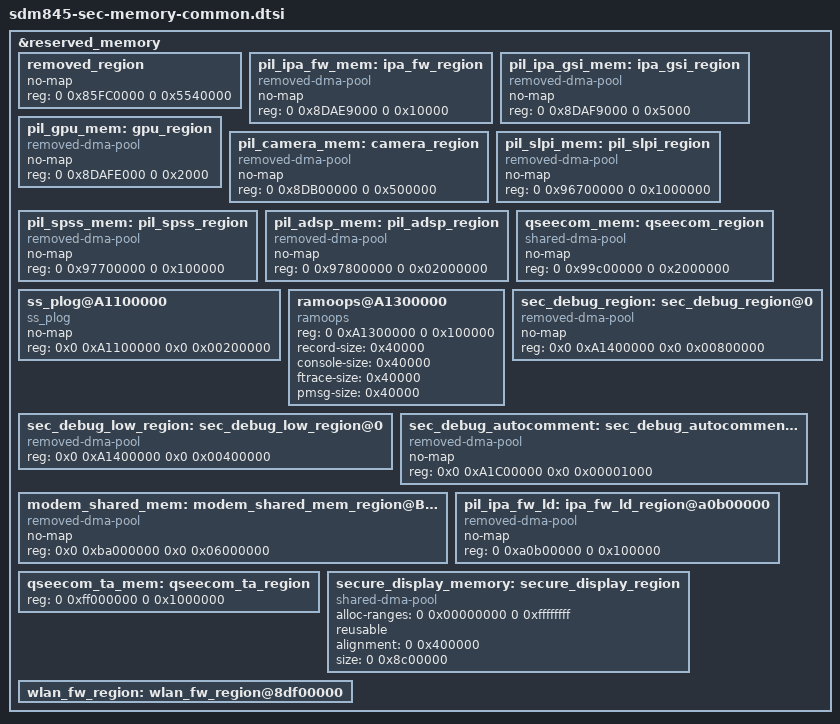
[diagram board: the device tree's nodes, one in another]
/* Copyright (c) 2016-2017, The Linux Foundation. All rights reserved.
 *
 * This program is free software; you can redistribute it and/or modify
 * it under the terms of the GNU General Public License version 2 and
 * only version 2 as published by the Free Software Foundation.
 *
 * This program is distributed in the hope that it will be useful,
 * but WITHOUT ANY WARRANTY; without even the implied warranty of
 * MERCHANTABILITY or FITNESS FOR A PARTICULAR PURPOSE.  See the
 * GNU General Public License for more details.
 */

&reserved_memory {
                /*
                 * Note: For TZapp, need to change XBL(QseeComDxe.h) and
                 *       TZ(oem_config.xml), too.
                 */
                /delete-node/ removed_region@85fc0000;
                removed_region: removed_region {
                        no-map;
                        reg = <0 0x85FC0000 0 0x5540000>;
                };

                /delete-node/ ipa_fw_region@8c400000;
                pil_ipa_fw_mem: ipa_fw_region {
                        compatible = "removed-dma-pool";
                        no-map;
                        reg = <0 0x8DAE9000 0 0x10000>;
                };

                /delete-node/ ipa_gsi_region@8c410000;
                pil_ipa_gsi_mem: ipa_gsi_region{
                        compatible = "removed-dma-pool";
                        no-map;
                        reg = <0 0x8DAF9000 0 0x5000>;
                };

                /delete-node/ gpu_region@8c415000;
                pil_gpu_mem: gpu_region {
                        compatible = "removed-dma-pool";
                        no-map;
                        reg = <0 0x8DAFE000 0 0x2000>;
                };

                /delete-node/ camera_region@8bf00000;
                pil_camera_mem: camera_region {
                        compatible = "removed-dma-pool";
                        no-map;
                        reg = <0 0x8DB00000 0 0x500000>;
                };

                /delete-node/ pil_slpi_region@96700000;
                pil_slpi_mem: pil_slpi_region{
                        compatible = "removed-dma-pool";
                        no-map;
                        reg = <0 0x96700000 0 0x1000000>;
                };

                /delete-node/ pil_spss_region@97b00000;
                pil_spss_mem: pil_spss_region {
                        compatible = "removed-dma-pool";
                        no-map;
                        reg = <0 0x97700000 0 0x100000>;
                };

                /delete-node/ pil_adsp_region@8c500000;
                pil_adsp_mem: pil_adsp_region {
                        compatible = "removed-dma-pool";
                        no-map;
                        reg = <0 0x97800000 0 0x02000000>;
                };

                /delete-node/ qseecom_region@8ab00000;
                qseecom_mem: qseecom_region {
                        compatible = "shared-dma-pool";
                        no-map;
                        reg = <0 0x99c00000 0 0x2000000>;
                };

                ss_plog@A1100000 {
                        compatible = "ss_plog";
                        no-map;
                        reg = <0x0 0xA1100000 0x0 0x00200000>;
                };

                ramoops@A1300000 {
                        compatible = "ramoops";
                        reg = <0 0xA1300000 0 0x100000>;
                        record-size = <0x40000>;
                        console-size = <0x40000>;
                        ftrace-size = <0x40000>;
                        pmsg-size = <0x40000>;
                };

                /* CONFIG_SEC_DEBUG reserves 8MB */
                sec_debug_region: sec_debug_region@0 {
                        compatible = "removed-dma-pool";
                        no-map;
                        reg = <0x0 0xA1400000 0x0 0x00800000>;
                };

                /* sec_debug_low_region reserves 4MB
                   This region is reserved if only debuglevel low */
                sec_debug_low_region: sec_debug_low_region@0 {
                        compatible = "removed-dma-pool";
                        reg = <0x0 0xA1400000 0x0 0x00400000>;
                };

                sec_debug_autocomment: sec_debug_autocomment@0 {
                        compatible = "removed-dma-pool";
                        no-map;
                        reg = <0x0 0xA1C00000 0x0 0x00001000>;
                };

                modem_shared_mem: modem_shared_mem_region@BA000000 {
                        compatible = "removed-dma-pool";
                        no-map;
                        reg = <0x0 0xba000000 0x0 0x06000000>;
                };

                pil_ipa_fw_ld: ipa_fw_ld_region@a0b00000 {
                        compatible = "removed-dma-pool";
                        no-map;
                        reg = <0 0xa0b00000 0 0x100000>;
                };

                /delete-node/ qseecom_ta_region;
                qseecom_ta_mem: qseecom_ta_region {
                        reg = <0 0xff000000 0 0x1000000>;
                };

                /delete-node/ secure_display_region;
                secure_display_memory: secure_display_region {
                        compatible = "shared-dma-pool";
                        alloc-ranges = <0 0x00000000 0 0xffffffff>;
                        reusable;
                        alignment = <0 0x400000>;
                        size = <0 0x8c00000>;
                };

                /*
                 * We need this region only if we use Qualcomm WiFi solution,
                 * otherwise no need.
                 */
                wlan_fw_region: wlan_fw_region@8df00000 {
                        /delete-property/ reg;
                };
         };
